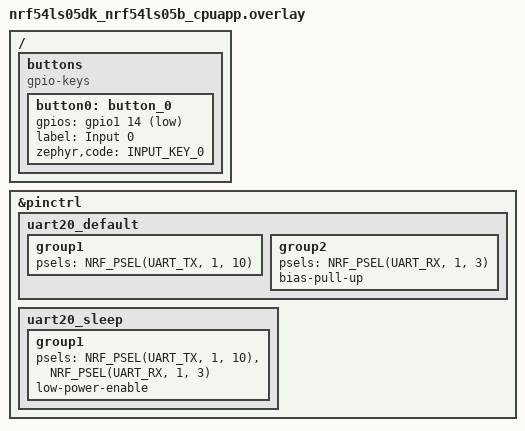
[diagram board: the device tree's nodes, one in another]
/ {
	/*
	 * Redefine sw0/button0 to use RXD0 - P1.14
	 * Thus, when sending character from host, there will be gpio interrupt,
	 * the same as originally triggered by sw0 button.
	 */
	buttons {
		compatible = "gpio-keys";

		button0: button_0 {
			gpios = <&gpio1 14 (GPIO_PULL_UP | GPIO_ACTIVE_LOW)>;
			label = "Input 0";
			zephyr,code = <INPUT_KEY_0>;
		};
	};
};

&pinctrl {
	/*
	 * Redefine: RXD0 -> P1.3 (any other valid pin)
	 */
	/omit-if-no-ref/ uart20_default: uart20_default {
		group1 {
			psels = <NRF_PSEL(UART_TX, 1, 10)>;
		};

		group2 {
			psels = <NRF_PSEL(UART_RX, 1, 3)>;
			bias-pull-up;
		};
	};

	/omit-if-no-ref/ uart20_sleep: uart20_sleep {
		group1 {
			psels = <NRF_PSEL(UART_TX, 1, 10)>,
				<NRF_PSEL(UART_RX, 1, 3)>;
			low-power-enable;
		};
	};
};
